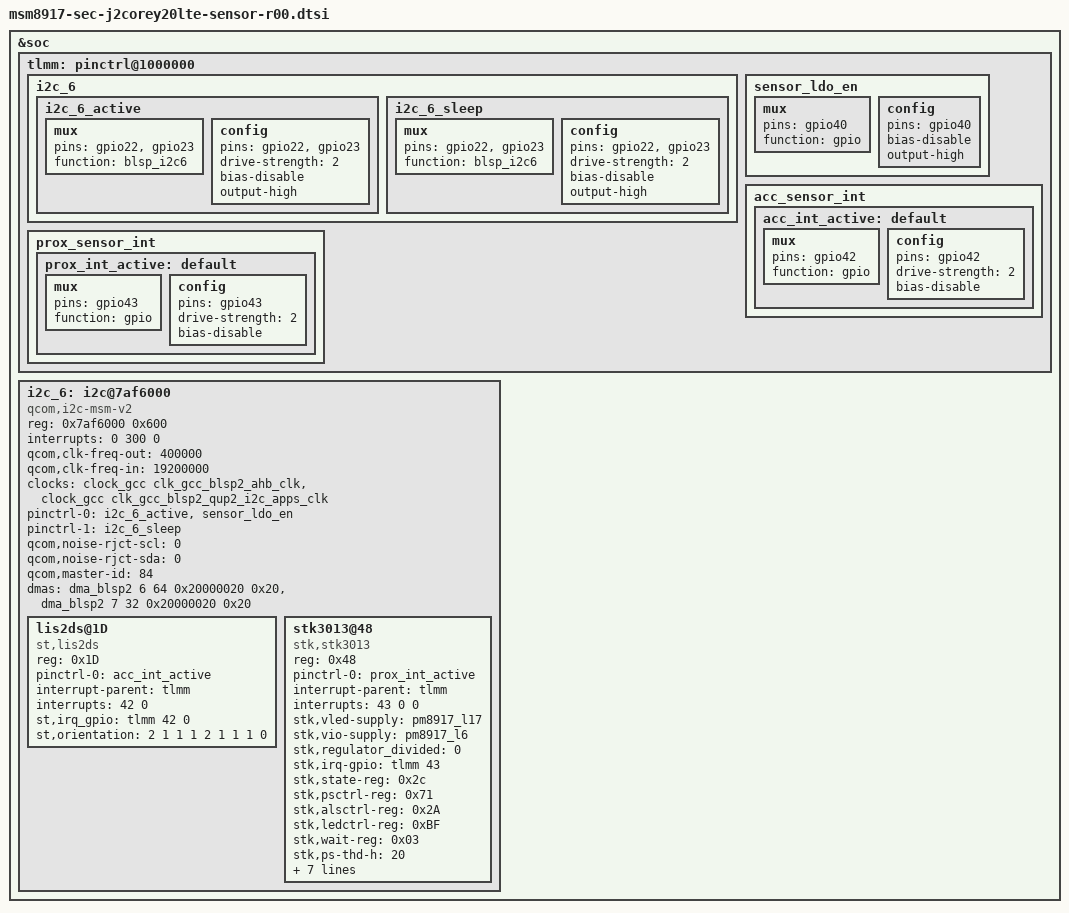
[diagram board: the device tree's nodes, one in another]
/* Copyright (c) 2017, The Linux Foundation. All rights reserved.
 *
 * This program is free software; you can redistribute it and/or modify
 * it under the terms of the GNU General Public License version 2 and
 * only version 2 as published by the Free Software Foundation.
 *
 * This program is distributed in the hope that it will be useful,
 * but WITHOUT ANY WARRANTY; without even the implied warranty of
 * MERCHANTABILITY or FITNESS FOR A PARTICULAR PURPOSE.  See the
 * GNU General Public License for more details.
 */


&soc {
	tlmm: pinctrl@1000000 {
	
		i2c_6 {
			i2c_6_active: i2c_6_active {
				/* active state */
				mux {
					pins = "gpio22", "gpio23";
					function = "blsp_i2c6";
				};

				config {
					pins = "gpio22", "gpio23";
					drive-strength = <2>;
					bias-disable;
					output-high;
				};
			};

			i2c_6_sleep: i2c_6_sleep {
				/* suspended state */
				mux {
					pins = "gpio22", "gpio23";
					function = "blsp_i2c6";
				};

				config {
					pins = "gpio22", "gpio23";
					drive-strength = <2>;
					bias-disable;
                    output-high;
				};
			};
		};
		
		/*Sensor Pins*/
		
		sensor_ldo_en: sensor_ldo_en {
			mux {
				pins = "gpio40";
				function = "gpio";
			};
			config {
				pins = "gpio40";
				bias-disable;
				output-high;
			};
		};

		acc_sensor_int {
			acc_int_active: default {
				mux {
					pins = "gpio42";
					function = "gpio";
				};

				config {
					pins = "gpio42";
					drive-strength = <2>;
					bias-disable;
				};
			};
		};

		prox_sensor_int {
			prox_int_active: default {
				mux {
					pins = "gpio43";
					function = "gpio";
				};

				config {
					pins = "gpio43";
					drive-strength = <2>;
					bias-disable;
				};
			};
		};
	
	};
	
	i2c_6: i2c@7af6000 { /* BLSP2 QUP2 */
		compatible = "qcom,i2c-msm-v2";
		#address-cells = <1>;
		#size-cells = <0>;
		reg-names = "qup_phys_addr";
		reg = <0x7af6000 0x600>;
		interrupt-names = "qup_irq";
		interrupts = <0 300 0>;
		qcom,clk-freq-out = <400000>;
		qcom,clk-freq-in  = <19200000>;
		clock-names = "iface_clk", "core_clk";
		clocks = <&clock_gcc clk_gcc_blsp2_ahb_clk>,
			<&clock_gcc clk_gcc_blsp2_qup2_i2c_apps_clk>;

		pinctrl-names = "i2c_active", "i2c_sleep";
		pinctrl-0 = <&i2c_6_active &sensor_ldo_en>;
		pinctrl-1 = <&i2c_6_sleep>;
		qcom,noise-rjct-scl = <0>;
		qcom,noise-rjct-sda = <0>;
		qcom,master-id = <84>;
		dmas = <&dma_blsp2 6 64 0x20000020 0x20>,
			<&dma_blsp2 7 32 0x20000020 0x20>;
		dma-names = "tx", "rx";
		status = "ok";

		lis2ds@1D {
			compatible = "st,lis2ds";
			reg = <0x1D>;
			pinctrl-names = "default";
			pinctrl-0 = <&acc_int_active>;
			interrupt-parent = <&tlmm>;
			interrupts = <42 0>;
			st,irq_gpio = <&tlmm 42 0>;
			st,orientation = <2 1 1 1 2 1 1 1 0>;
		};
		

		stk3013@48 {
			compatible = "stk,stk3013";
			reg = <0x48>;
			pinctrl-names = "default";
			pinctrl-0 = <&prox_int_active>;
			interrupt-parent =  <&tlmm>;
			interrupts = <43 0 0>;
			stk,vled-supply = <&pm8917_l17>;
			stk,vio-supply = <&pm8917_l6>;
			stk,regulator_divided = <0>;
			stk,irq-gpio = <&tlmm 43 0>;
			stk,state-reg = <0x2c>;
			stk,psctrl-reg = <0x71>;
			stk,alsctrl-reg = <0x2A>;
			stk,ledctrl-reg = <0xBF>;
			stk,wait-reg = <0x03>;
			stk,ps-thd-h = <20>;
			stk,ps-thd-l = <10>;
			stk,ps-cancel-thd-h = <10>;
			stk,ps-cancel-thd-l = <7>;
			stk,ps-cal-skip-adc = <7>;
			stk,ps-cal-fail-adc = <23>;
			stk,ps-default-offset = <3>;
			stk,transmittance = <500>;
		};
	};
};
